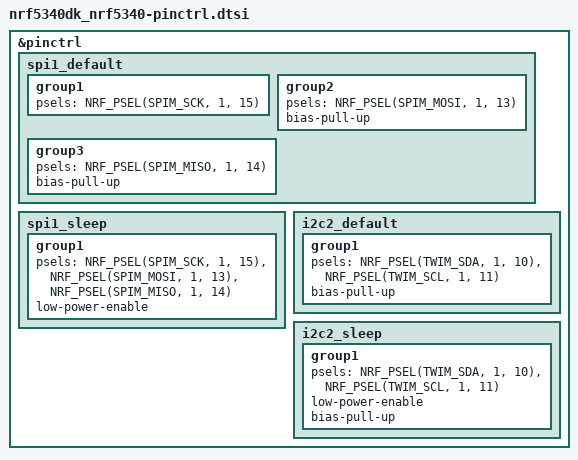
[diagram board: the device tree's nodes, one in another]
&pinctrl {
	spi1_default: spi1_default {
		group1 {
			psels = <NRF_PSEL(SPIM_SCK, 1, 15)>;
		};
		group2 {
			psels = <NRF_PSEL(SPIM_MOSI, 1, 13)>;
			bias-pull-up;
		};
		group3 {
			psels = <NRF_PSEL(SPIM_MISO, 1, 14)>;
			bias-pull-up;
		};
	};

	spi1_sleep: spi1_sleep {
		group1 {
			psels = <NRF_PSEL(SPIM_SCK, 1, 15)>,
				<NRF_PSEL(SPIM_MOSI, 1, 13)>,
				<NRF_PSEL(SPIM_MISO, 1, 14)>;
			low-power-enable;
		};
	};

	i2c2_default: i2c2_default {
		group1 {
			psels = <NRF_PSEL(TWIM_SDA, 1, 10)>,
				<NRF_PSEL(TWIM_SCL, 1, 11)>;
	        bias-pull-up;
		};
	};

	i2c2_sleep: i2c2_sleep {
		group1 {
			psels = <NRF_PSEL(TWIM_SDA, 1, 10)>,
				<NRF_PSEL(TWIM_SCL, 1, 11)>;
			low-power-enable;
	        bias-pull-up;
		};
	};

};
